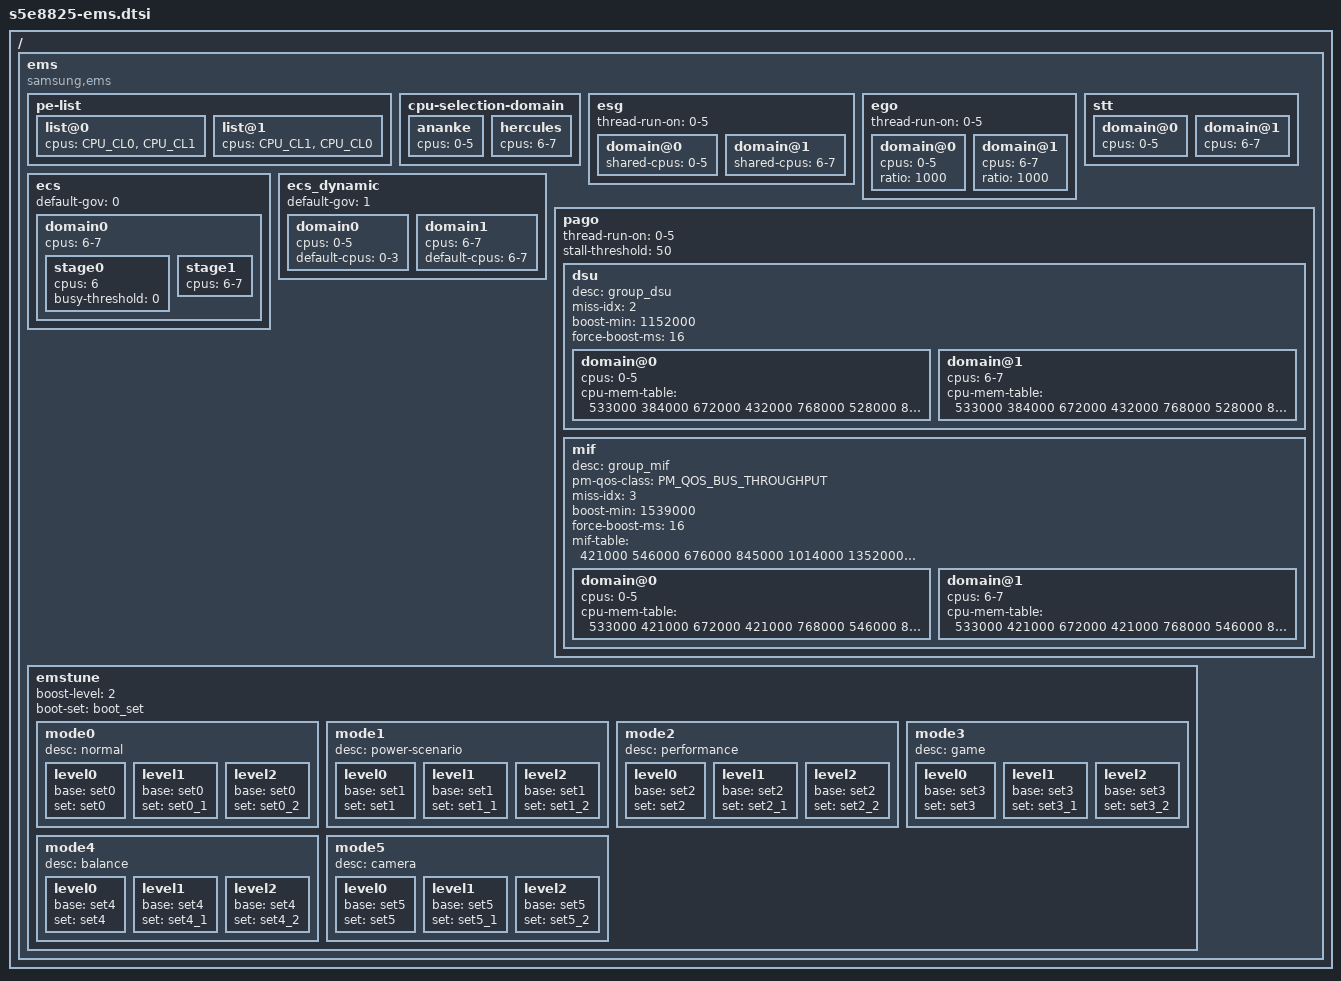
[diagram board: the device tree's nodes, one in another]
/*
 * SAMSUNG EXYNOS SoC EMS device tree source
 *
 * Copyright (c) 2019 Samsung Electronics Co., Ltd.
 *             http://www.samsung.com
 *
 * SAMSUNG EXYNOS SoC EMS device nodes are listed in this file.
 * EXYNOS based board files should include this file.
 *
 * This program is free software; you can redistribute it and/or modify
 * it under the terms of the GNU General Public License version 2 as
 * published by the Free Software Foundation.
 *
 */
#include <dt-bindings/soc/samsung/ems.h>

#include "emstune/s5e8825/sets.dtsi"

/ {
	ems {
		compatible = "samsung,ems";
		status = "okay";

		pe-list {
			#define CPU_CL0 "0-5"
			#define CPU_CL1 "6-7"

			list@0 {
				cpus = CPU_CL0, CPU_CL1;
			};
			list@1 {
				cpus = CPU_CL1, CPU_CL0;
			};
		};

		cpu-selection-domain {
			ananke {
				cpus = "0-5";
			};
			hercules {
				cpus = "6-7";
			};
		};

		esg {
			thread-run-on = "0-5";

			domain@0 {
				shared-cpus = "0-5";
			};
			domain@1 {
				shared-cpus = "6-7";
			};
		};

		ego {
			thread-run-on = "0-5";

			domain@0 {
				cpus = "0-5";
				ratio = < 1000 >;
			};
			domain@1 {
				cpus = "6-7";
				ratio = < 1000 >;
			};
		};

		stt {
			domain@0 {
				cpus = "0-5";
			};
			domain@1 {
				cpus = "6-7";
			};
		};

		ecs {
			default-gov = < 0 >;

			domain0 {
				cpus = "6-7";

				stage0 {
					cpus = "6";
					busy-threshold = <0>;
				};
				stage1 {
					cpus = "6-7";
				};
			};
		};

		ecs_dynamic {
			default-gov = < 1 >;

			domain0 {
				cpus = "0-5";
				default-cpus = "0-3";
			};
			domain1 {
				cpus = "6-7";
				default-cpus = "6-7";
			};
		};

		pago {
			thread-run-on = "0-5";
			stall-threshold = <50>;

			dsu {
				desc = "group_dsu";
				miss-idx = <2>;
				boost-min = <1152000>;
				force-boost-ms = <16>;

				domain@0 {
					cpus = "0-5";
					cpu-mem-table = <						533000    384000    672000    432000    768000    528000    864000    576000
						960000    624000   1056000    720000   1152000    768000   1248000    816000
						1344000    912000   1440000    960000   1536000   1008000   1632000   1104000
						1728000   1152000   1824000   1200000   1920000   1248000   2002000   1344000 >;
				};
				domain@1 {
					cpus = "6-7";
					cpu-mem-table = <						533000    384000    672000    432000    768000    528000    864000    576000
						960000    624000   1056000    720000   1152000    768000   1248000    816000
						1344000    912000   1440000    960000   1536000   1008000   1632000   1104000
						1728000   1152000   1824000   1200000   1920000   1248000   2016000   1344000
						2112000   1344000   2208000   1440000   2288000   1536000   2400000   1632000 >;
				};
			};

			mif {
				desc = "group_mif";
				pm-qos-class = <PM_QOS_BUS_THROUGHPUT>;
				miss-idx = <3>;
				boost-min = <1539000>;
				force-boost-ms = <16>;
				mif-table = < 421000 546000 676000 845000 1014000
					     1352000 1539000 1794000 2093000 >;

				domain@0 {
					cpus = "0-5";
					cpu-mem-table = <						533000    421000    672000    421000    768000    546000    864000    546000
						960000    676000   1056000    676000   1152000    845000   1248000    845000
						1344000    845000   1440000    845000   1536000   1014000   1632000   1014000
						1728000   1014000   1824000   1352000   1920000   1352000   2002000   1539000 >;
				};
				domain@1 {
					cpus = "6-7";
					cpu-mem-table = <						533000    421000    672000    421000    768000    546000    864000    546000
						960000    845000   1056000   1014000   1152000   1014000   1248000   1014000
						1344000   1352000   1440000   1352000   1536000   1352000   1632000   1539000
						1728000   1539000   1824000   1794000   1920000   1794000   2016000   1794000
						2112000   1794000   2208000   1794000   2288000   2093000   2400000   2093000 >;
				};
			};
		};

		emstune {
			boost-level = <2>;
			boot-set = <&boot_set>;

			mode0 {
				desc = "normal";

				level0 {
					base = <&set0>;
					set = <&set0>;
				};
				level1 {
					base = <&set0>;
					set = <&set0_1>;
				};
				level2 {
					base = <&set0>;
					set = <&set0_2>;
				};
			};
			mode1 {
				desc = "power-scenario";

				level0 {
					base = <&set1>;
					set = <&set1>;
				};
				level1 {
					base = <&set1>;
					set = <&set1_1>;
				};
				level2 {
					base = <&set1>;
					set = <&set1_2>;
				};
			};
			mode2 {
				desc = "performance";

				level0 {
					base = <&set2>;
					set = <&set2>;
				};
				level1 {
					base = <&set2>;
					set = <&set2_1>;
				};
				level2 {
					base = <&set2>;
					set = <&set2_2>;
				};
			};
			mode3 {
				desc = "game";

				level0 {
					base = <&set3>;
					set = <&set3>;
				};
				level1 {
					base = <&set3>;
					set = <&set3_1>;
				};
				level2 {
					base = <&set3>;
					set = <&set3_2>;
				};
			};
			mode4 {
				desc = "balance";

				level0 {
					base = <&set4>;
					set = <&set4>;
				};
				level1 {
					base = <&set4>;
					set = <&set4_1>;
				};
				level2 {
					base = <&set4>;
					set = <&set4_2>;
				};
			};
			mode5 {
				desc = "camera";

				level0 {
					base = <&set5>;
					set = <&set5>;
				};
				level1 {
					base = <&set5>;
					set = <&set5_1>;
				};
				level2 {
					base = <&set5>;
					set = <&set5_2>;
				};
			};
		};
	};
};
